AUTOSAR XML (schema 4-2-1)
package /WdgM_Test
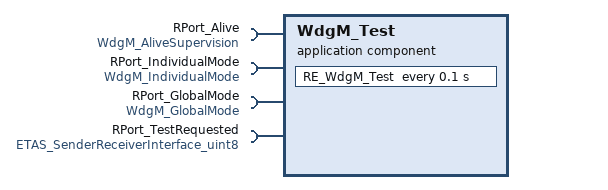
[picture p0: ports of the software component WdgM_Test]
  application sw component type WdgM_Test
    4 x require port:
      RPort_Alive: required-interface=WdgM_AliveSupervision
      RPort_IndividualMode: required-interface=WdgM_IndividualMode
      RPort_GlobalMode: required-interface=WdgM_GlobalMode
      RPort_TestRequested: required-interface=ETAS_SenderReceiverInterface_uint8
    behavior WdgM_Test_IB: data-type-mapping=WdgM_Type_Map
      timing event TimingEvent: start-on-event=RE_WdgM_Test, period=0.1
      runnable RE_WdgM_Test: mode-access-points=[RPort_GlobalMode.currentMode, RPort_IndividualMode.currentMode], symbol=WdgM_Test_func
        data-read-access:
          access DRA_uint8_0: accessed-variable=RPort_TestRequested.uint8
        sync call SynchronousServerCallPoint_0: operation=RPort_Alive.CheckpointReached
